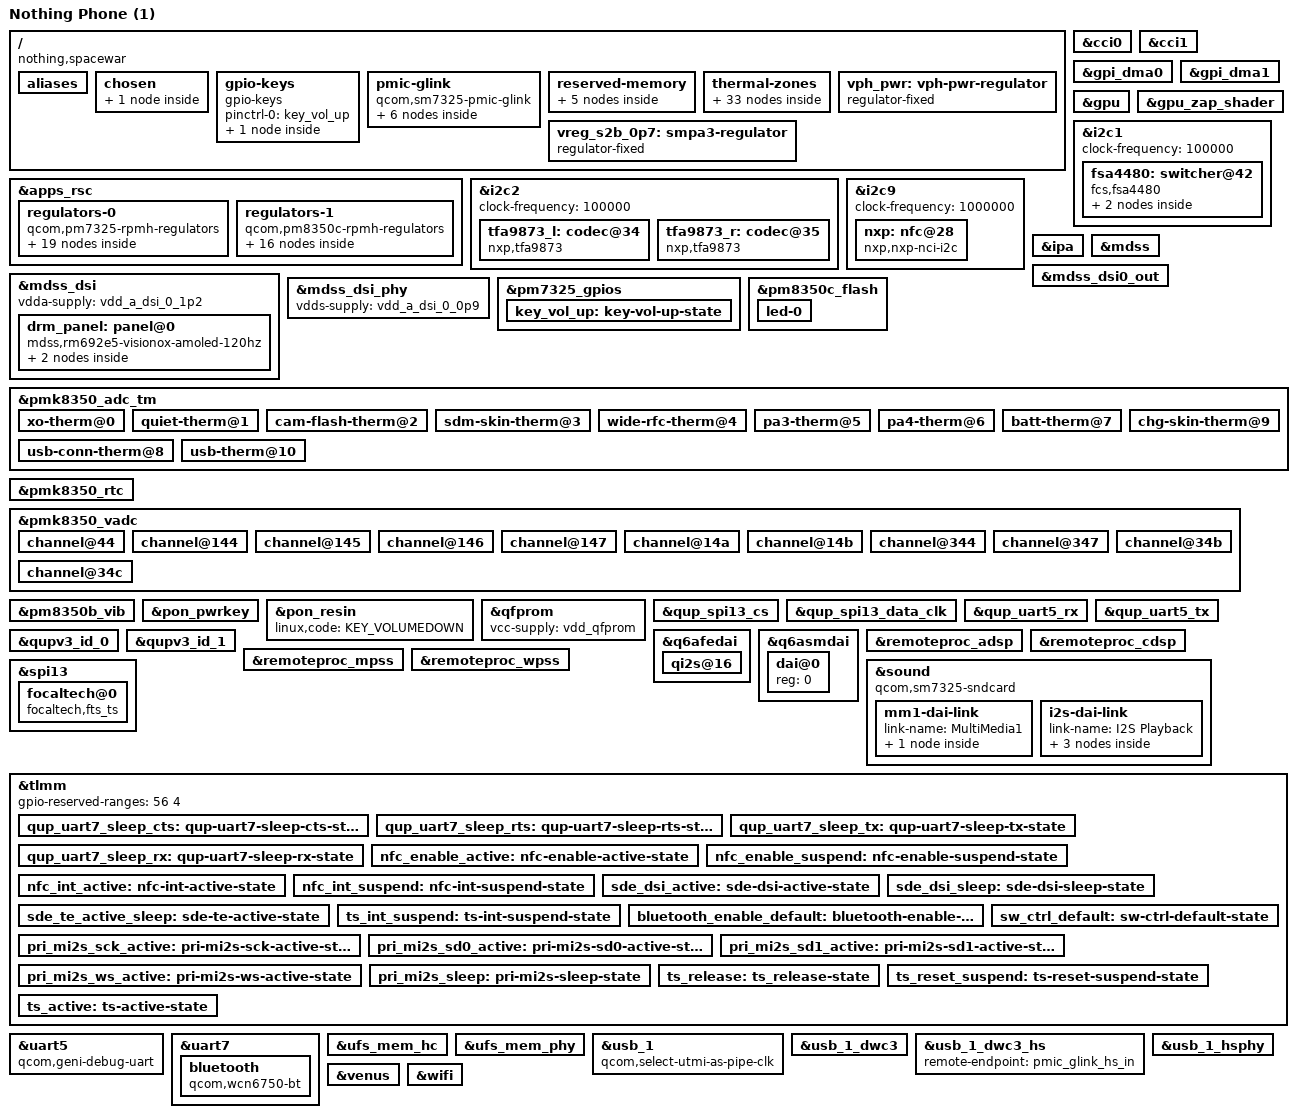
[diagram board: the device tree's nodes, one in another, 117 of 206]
// SPDX-License-Identifier: BSD-3-Clause
/*
 * Copyright (c) 2024, Eugene Lepshy <fekz115@gmail.com>
 * Copyright (c) 2024, Danila Tikhonov <danila@jiaxyga.com>
 */

/dts-v1/;

#include <dt-bindings/arm/qcom,ids.h>
#include <dt-bindings/gpio/gpio.h>
#include <dt-bindings/regulator/qcom,rpmh-regulator.h>
#include <dt-bindings/sound/qcom,q6afe.h>
#include <dt-bindings/sound/qcom,q6asm.h>
#include <dt-bindings/leds/common.h>

#include <dt-bindings/iio/qcom,spmi-adc7-pm7325.h>
#include <dt-bindings/iio/qcom,spmi-adc7-pm8350b.h>
#include <dt-bindings/iio/qcom,spmi-adc7-pmk8350.h>
#include <dt-bindings/pinctrl/qcom,pmic-gpio.h>
#include "sm7325.dtsi"
#include "pm7325.dtsi"
#include "pm8350b.dtsi" /* PM7325B */
#include "pm8350c.dtsi" /* PM7350C */
#include "pmk8350.dtsi" /* PMK7325 */

/delete-node/ &rmtfs_mem;

/ {
	model = "Nothing Phone (1)";
	compatible = "nothing,spacewar", "qcom,sm7325";
	qcom,msm-id = <QCOM_ID_SM7325 0x10000>;
	qcom,board-id = <0x1000b 0>;
	chassis-type = "handset";

	aliases {
		serial0 = &uart5;
		serial1 = &uart7;
	};

	chosen {
		#address-cells = <2>;
		#size-cells = <2>;
		ranges;

		stdout-path = "serial0:115200n8";
		bootargs = "earlycon console=tty0 PMOS_NOSPLASH";

		framebuffer@e1000000 {
			compatible = "simple-framebuffer";
			reg = <0x0 0xe1000000 0x0 (1080 * 2400 * 4)>;
			width = <1080>;
			height = <2400>;
			stride = <(1080 * 4)>;
			format = "a8r8g8b8";
		};
	};

	gpio-keys {
		compatible = "gpio-keys";

		pinctrl-0 = <&key_vol_up>;
		pinctrl-names = "default";

		key-volume-up {
			label = "Volume up";
			gpios = <&pm7325_gpios 6 GPIO_ACTIVE_LOW>;
			linux,code = <KEY_VOLUMEUP>;
		};
	};

	pmic-glink {
		compatible = "qcom,sm7325-pmic-glink",
			     "qcom,pmic-glink";

		#address-cells = <1>;
		#size-cells = <0>;

		connector@0 {
			compatible = "usb-c-connector";
			reg = <0>;
			power-role = "dual";
			data-role = "dual";

			ports {
				#address-cells = <1>;
				#size-cells = <0>;

				port@0 {
					reg = <0>;

					pmic_glink_hs_in: endpoint {
						remote-endpoint = <&usb_1_dwc3_hs>;
					};
				};

				port@1 {
					reg = <1>;

					pmic_glink_sbu: endpoint {
						remote-endpoint = <&fsa4480_sbu_mux>;
					};
				};
			};
		};
	};

	reserved-memory {
		#address-cells = <2>;
		#size-cells = <2>;
		ranges;

		ramoops@83a00000 {
			compatible = "ramoops";
			reg = <0x0 0x83a00000 0x0 0x400000>;
			pmsg-size = <0x200000>;
			mem-type = <0x02>;
			console-size = <0x200000>;
		};

		cdsp_mem: cdsp@88f00000 {
			reg = <0x0 0x88f00000 0x0 0x1e00000>;
			no-map;
		};

		removed_mem: removed@c0000000 {
			reg = <0x0 0xc0000000 0x0 0x5100000>;
			no-map;
		};

		framebuffer@e1000000 {
			reg = <0x0 0xe1000000 0x0 (1080 * 2400 * 4)>;
			no-map;
		};

		rmtfs_mem: rmtfs@f8500000 {
			compatible = "qcom,rmtfs-mem";
			reg = <0x0 0xf8500000 0x0 0x600000>;
			no-map;

			qcom,client-id = <1>;
			qcom,vmid = <QCOM_SCM_VMID_MSS_MSA>,
				    <QCOM_SCM_VMID_NAV>;
		};
	};

	thermal-zones {
		batt-thermal {
			polling-delay-passive = <0>;
			polling-delay = <0>;
			thermal-sensors = <&pmk8350_adc_tm 7>;

			trips {
				active-config0 {
					temperature = <125000>;
					hysteresis = <1000>;
					type = "passive";
				};
			};
		};

		camera-thermal {
			polling-delay-passive = <0>;
			polling-delay = <0>;
			thermal-sensors = <&pmk8350_adc_tm 2>;

			trips {
				active-config0 {
					temperature = <125000>;
					hysteresis = <1000>;
					type = "passive";
				};
			};
		};

		chg-skin-thermal {
			polling-delay-passive = <0>;
			polling-delay = <0>;
			thermal-sensors = <&pmk8350_adc_tm 9>;

			trips {
				active-config0 {
					temperature = <125000>;
					hysteresis = <1000>;
					type = "passive";
				};
			};
		};

		conn-thermal {
			polling-delay-passive = <0>;
			polling-delay = <0>;
			thermal-sensors = <&pmk8350_adc_tm 8>;

			trips {
				active-config0 {
					temperature = <125000>;
					hysteresis = <1000>;
					type = "passive";
				};
			};
		};

		pa3-thermal {
			polling-delay-passive = <0>;
			polling-delay = <0>;
			thermal-sensors = <&pmk8350_adc_tm 5>;

			trips {
				active-config0 {
					temperature = <125000>;
					hysteresis = <1000>;
					type = "passive";
				};
			};
		};

		pa4-thermal {
			polling-delay-passive = <0>;
			polling-delay = <0>;
			thermal-sensors = <&pmk8350_adc_tm 6>;

			trips {
				active-config0 {
					temperature = <125000>;
					hysteresis = <1000>;
					type = "passive";
				};
			};
		};

		quiet-thermal {
			polling-delay-passive = <0>;
			polling-delay = <0>;
			thermal-sensors = <&pmk8350_adc_tm 1>;

			trips {
				active-config0 {
					temperature = <125000>;
					hysteresis = <1000>;
					type = "passive";
				};
			};
		};

		rear-cam-thermal {
			polling-delay-passive = <0>;
			polling-delay = <0>;
			thermal-sensors = <&pmk8350_adc_tm 4>;

			trips {
				active-config0 {
					temperature = <125000>;
					hysteresis = <1000>;
					type = "passive";
				};
			};
		};

		sdm-skin-thermal {
			polling-delay-passive = <0>;
			polling-delay = <0>;
			thermal-sensors = <&pmk8350_adc_tm 3>;

			trips {
				active-config0 {
					temperature = <125000>;
					hysteresis = <1000>;
					type = "passive";
				};
			};
		};

		usb-thermal {
			polling-delay-passive = <0>;
			polling-delay = <0>;
			thermal-sensors = <&pmk8350_adc_tm 10>;

			trips {
				active-config0 {
					temperature = <125000>;
					hysteresis = <1000>;
					type = "passive";
				};
			};
		};

		xo-thermal {
			polling-delay-passive = <0>;
			polling-delay = <0>;
			thermal-sensors = <&pmk8350_adc_tm 0>;

			trips {
				active-config0 {
					temperature = <125000>;
					hysteresis = <1000>;
					type = "passive";
				};
			};
		};
	};

	vph_pwr: vph-pwr-regulator {
		compatible = "regulator-fixed";
		regulator-name = "vph_pwr";
		regulator-min-microvolt = <3700000>;
		regulator-max-microvolt = <3700000>;
	};

	// S2B is really ebi.lvl but it's there for supply map completeness sake.
	vreg_s2b_0p7: smpa3-regulator {
		compatible = "regulator-fixed";
		regulator-name = "vreg_s2b_0p7";

		regulator-min-microvolt = <65535>;
		regulator-max-microvolt = <65535>;
		regulator-always-on;
		vin-supply = <&vph_pwr>;
	};
};

&apps_rsc {
	regulators-0 {
		compatible = "qcom,pm7325-rpmh-regulators";
		qcom,pmic-id = "b";

		vdd-s1-supply = <&vph_pwr>;
		vdd-s2-supply = <&vph_pwr>;
		vdd-s7-supply = <&vph_pwr>;
		vdd-s8-supply = <&vph_pwr>;

		vdd-l1-l4-l12-l15-supply = <&vreg_s7b_0p952>;
		vdd-l2-l7-supply = <&vreg_bob>;
		vdd-l3-supply = <&vreg_s2b_0p7>;
		vdd-l5-supply = <&vreg_s2b_0p7>;
		vdd-l6-l9-l10-supply = <&vreg_s8b_1p256>;
		vdd-l8-supply = <&vreg_s7b_0p952>;
		vdd-l11-l17-l18-l19-supply = <&vreg_s1b_1p856>;
		vdd-l13-supply = <&vreg_s7b_0p952>;
		vdd-l14-l16-supply = <&vreg_s8b_1p256>;

		/*
		 * S2, L4-L5 are ARCs:
		 * S2 - ebi.lvl,
		 * L4 - lmx.lvl,
		 * l5 - lcx.lvl.
		 *
		 * L10 are unused.
		 */

		vdd19_pmu_rfa_i:
		vreg_s1b_1p856: smps1 {
			regulator-min-microvolt = <1840000>;
			regulator-max-microvolt = <2040000>;
		};

		vreg_s7b_0p952: smps7 {
			regulator-min-microvolt = <535000>;
			regulator-max-microvolt = <1120000>;
		};

		vdd13_pmu_rfa_i:
		vreg_s8b_1p256: smps8 {
			regulator-min-microvolt = <1200000>;
			regulator-max-microvolt = <1500000>;
			regulator-initial-mode = <RPMH_REGULATOR_MODE_RET>;
		};

		vreg_l1b_0p912: ldo1 {
			regulator-min-microvolt = <825000>;
			regulator-max-microvolt = <925000>;
			regulator-initial-mode = <RPMH_REGULATOR_MODE_HPM>;
		};

		vdd_a_usbhs_3p1:
		vreg_l2b_3p072: ldo2 {
			regulator-min-microvolt = <2700000>;
			regulator-max-microvolt = <3544000>;
			regulator-initial-mode = <RPMH_REGULATOR_MODE_HPM>;
		};

		vreg_l3b_0p6: ldo3 {
			regulator-min-microvolt = <312000>;
			regulator-max-microvolt = <910000>;
			regulator-initial-mode = <RPMH_REGULATOR_MODE_HPM>;
		};

		vdd_a_dsi_0_1p2:
		vdd_a_ufs_0_1p2:
		vreg_l6b_1p2: ldo6 {
			regulator-min-microvolt = <1140000>;
			regulator-max-microvolt = <1260000>;
			regulator-initial-mode = <RPMH_REGULATOR_MODE_HPM>;
			regulator-allow-set-load;
			regulator-allowed-modes = <RPMH_REGULATOR_MODE_LPM
						   RPMH_REGULATOR_MODE_HPM>;
		};

		vreg_l7b_2p96: ldo7 {
			regulator-min-microvolt = <2952000>;
			regulator-max-microvolt = <2952000>;
			regulator-initial-mode = <RPMH_REGULATOR_MODE_HPM>;
			regulator-allow-set-load;
			regulator-allowed-modes = <RPMH_REGULATOR_MODE_LPM
						   RPMH_REGULATOR_MODE_HPM>;
		};

		vreg_l8b_0p904: ldo8 {
			regulator-min-microvolt = <870000>;
			regulator-max-microvolt = <970000>;
			regulator-initial-mode = <RPMH_REGULATOR_MODE_HPM>;
		};

		vreg_l9b_1p2: ldo9 {
			regulator-min-microvolt = <1200000>;
			regulator-max-microvolt = <1304000>;
			regulator-initial-mode = <RPMH_REGULATOR_MODE_HPM>;
			regulator-allow-set-load;
			regulator-allowed-modes = <RPMH_REGULATOR_MODE_LPM
						   RPMH_REGULATOR_MODE_HPM>;
		};

		vreg_l11b_1p776: ldo11 {
			regulator-min-microvolt = <1504000>;
			regulator-max-microvolt = <2000000>;
			regulator-initial-mode = <RPMH_REGULATOR_MODE_HPM>;
		};

		vreg_l12b_0p8: ldo12 {
			regulator-min-microvolt = <751000>;
			regulator-max-microvolt = <824000>;
			regulator-initial-mode = <RPMH_REGULATOR_MODE_HPM>;
		};

		vreg_l13b_0p8: ldo13 {
			regulator-min-microvolt = <530000>;
			regulator-max-microvolt = <824000>;
			regulator-initial-mode = <RPMH_REGULATOR_MODE_HPM>;
		};

		vreg_l14b_1p2: ldo14 {
			regulator-min-microvolt = <1080000>;
			regulator-max-microvolt = <1304000>;
			regulator-initial-mode = <RPMH_REGULATOR_MODE_HPM>;
		};

		vreg_l15b_0p88: ldo15 {
			regulator-min-microvolt = <765000>;
			regulator-max-microvolt = <1020000>;
			regulator-initial-mode = <RPMH_REGULATOR_MODE_HPM>;
		};

		vreg_l16b_1p2: ldo16 {
			regulator-min-microvolt = <1100000>;
			regulator-max-microvolt = <1300000>;
			regulator-initial-mode = <RPMH_REGULATOR_MODE_HPM>;
		};

		vreg_l17b_1p8: ldo17 {
			regulator-min-microvolt = <1700000>;
			regulator-max-microvolt = <1900000>;
			regulator-initial-mode = <RPMH_REGULATOR_MODE_HPM>;
		};

		vreg_l18b_1p8: ldo18 {
			regulator-min-microvolt = <1800000>;
			regulator-max-microvolt = <2000000>;
			regulator-initial-mode = <RPMH_REGULATOR_MODE_HPM>;
		};

		vreg_l19b_1p8: ldo19 {
			regulator-min-microvolt = <1800000>;
			regulator-max-microvolt = <2000000>;
			regulator-initial-mode = <RPMH_REGULATOR_MODE_HPM>;
		};
	};

	regulators-1 {
		compatible = "qcom,pm8350c-rpmh-regulators";
		qcom,pmic-id = "c";

		vdd-s1-supply = <&vph_pwr>;
		vdd-s2-supply = <&vph_pwr>;
		vdd-s5-supply = <&vph_pwr>;
		vdd-s7-supply = <&vph_pwr>;
		vdd-s9-supply = <&vph_pwr>;
		vdd-s10-supply = <&vph_pwr>;

		vdd-l1-l12-supply = <&vreg_s1b_1p856>;
		vdd-l2-l8-supply = <&vreg_s1b_1p856>;
		/*
		 * Doesn't work :/
		 * vdd-l3-l4-l5-l7-l13-supply = <&vreg_bob>;
		 */
		vdd-l6-l9-l11-supply = <&vreg_bob>;
		vdd-l10-supply = <&vreg_s7b_0p952>;

		vdd-bob-supply = <&vph_pwr>;

		/*
		 * S2, S5, S7, S10 are ARCs:
		 * S2 - cx.lvl,
		 * S5 - mss.lvl,
		 * S7 - gfx.lvl,
		 * S10 - mx.lvl.
		 */

		vreg_s1c_2p2: smps1 {
			regulator-min-microvolt = <2190000>;
			regulator-max-microvolt = <2210000>;
		};

		vreg_s9c_0p676: smps9 {
			regulator-min-microvolt = <1010000>;
			regulator-max-microvolt = <1170000>;
		};

		vdd_a_usbhs_1p8:
		vdd_qfprom:
		vreg_l1c_1p8: ldo1 {
			regulator-min-microvolt = <1800000>;
			regulator-max-microvolt = <1980000>;
			regulator-initial-mode = <RPMH_REGULATOR_MODE_HPM>;
		};

		vreg_l2c_1p8: ldo2 {
			regulator-min-microvolt = <1620000>;
			regulator-max-microvolt = <1980000>;
			regulator-initial-mode = <RPMH_REGULATOR_MODE_HPM>;
		};

		vreg_l3c_3p0: ldo3 {
			regulator-min-microvolt = <2800000>;
			regulator-max-microvolt = <3540000>;
			regulator-initial-mode = <RPMH_REGULATOR_MODE_HPM>;
			regulator-always-on;
		};

		vreg_l4c_1p8_3p0: ldo4 {
			regulator-min-microvolt = <1620000>;
			regulator-max-microvolt = <3300000>;
			regulator-initial-mode = <RPMH_REGULATOR_MODE_HPM>;
		};

		vreg_l5c_1p8_3p0: ldo5 {
			regulator-min-microvolt = <1620000>;
			regulator-max-microvolt = <3300000>;
			regulator-initial-mode = <RPMH_REGULATOR_MODE_HPM>;
		};

		vreg_l6c_2p96: ldo6 {
			regulator-min-microvolt = <1650000>;
			regulator-max-microvolt = <3544000>;
			regulator-initial-mode = <RPMH_REGULATOR_MODE_HPM>;
		};

		vreg_l7c_3p0: ldo7 {
			regulator-min-microvolt = <3000000>;
			regulator-max-microvolt = <3544000>;
			regulator-initial-mode = <RPMH_REGULATOR_MODE_HPM>;
		};

		vreg_l8c_1p8: ldo8 {
			regulator-min-microvolt = <1620000>;
			regulator-max-microvolt = <2000000>;
			regulator-initial-mode = <RPMH_REGULATOR_MODE_HPM>;
			regulator-always-on;
		};

		vreg_l9c_2p96: ldo9 {
			regulator-min-microvolt = <2700000>;
			regulator-max-microvolt = <3544000>;
			regulator-initial-mode = <RPMH_REGULATOR_MODE_HPM>;
		};

		vdd_a_dsi_0_0p9:
		vdd_a_dsi_0_pll_0p9:
		vdd_a_ufs_0_core:
		vdd_a_usbhs_core:
		vreg_l10c_0p88: ldo10 {
			regulator-min-microvolt = <720000>;
			regulator-max-microvolt = <1050000>;
			regulator-initial-mode = <RPMH_REGULATOR_MODE_HPM>;
			regulator-allow-set-load;
			regulator-allowed-modes = <RPMH_REGULATOR_MODE_LPM
						   RPMH_REGULATOR_MODE_HPM>;
		};

		vreg_l11c_2p8: ldo11 {
			regulator-min-microvolt = <2800000>;
			regulator-max-microvolt = <3544000>;
			regulator-initial-mode = <RPMH_REGULATOR_MODE_HPM>;
		};

		vreg_l12c_1p8: ldo12 {
			regulator-min-microvolt = <1650000>;
			regulator-max-microvolt = <2000000>;
			regulator-initial-mode = <RPMH_REGULATOR_MODE_HPM>;
		};

		vreg_l13c_3p0: ldo13 {
			regulator-min-microvolt = <2700000>;
			regulator-max-microvolt = <3544000>;
			regulator-initial-mode = <RPMH_REGULATOR_MODE_HPM>;
		};

		vdd_flash:
		vdd_iris_rgb:
		vdd_mic_bias:
		vreg_bob: bob {
			regulator-min-microvolt = <3008000>;
			regulator-max-microvolt = <3960000>;
			regulator-initial-mode = <RPMH_REGULATOR_MODE_AUTO>;
		};
	};
};

&cci0 {
	status = "okay";
};

&cci1 {
	status = "okay";
};

&gpi_dma0 {
	status = "okay";
};

&gpi_dma1 {
	status = "okay";
};

&gpu {
	status = "okay";
};

&gpu_zap_shader {
	firmware-name = "qcom/sm7325/nothing/spacewar/a660_zap.mbn";
};

&i2c1 {
	clock-frequency = <100000>;
	status = "okay";

	/* awinic,aw210xx_led @ 20 */

	fsa4480: switcher@42 {
		compatible = "fcs,fsa4480";
		reg = <0x42>;

		vcc-supply = <&vreg_bob>;

		mode-switch;
		orientation-switch;

		port {
			fsa4480_sbu_mux: endpoint {
				remote-endpoint = <&pmic_glink_sbu>;
			};
		};
	};
};

&i2c2 {
	clock-frequency = <100000>;
	status = "okay";

	tfa9873_l: codec@34 { /* EAR */
		compatible = "nxp,tfa9873", "nxp,tfa9872";
		reg = <0x34>;
		reset-gpio = <&tlmm 101 GPIO_ACTIVE_HIGH>;

		#sound-dai-cells = <1>;
	};

	tfa9873_r: codec@35 { /* SPK */
		compatible = "nxp,tfa9873", "nxp,tfa9872";
		reg = <0x35>;
		reset-gpio = <&tlmm 101 GPIO_ACTIVE_HIGH>;

		#sound-dai-cells = <1>;
	};
};

&i2c9 {
	clock-frequency = <1000000>;
	status = "okay";

	nxp: nfc@28 {
		compatible = "nxp,nxp-nci-i2c";
		reg = <0x28>;

		interrupt-parent = <&tlmm>;
		interrupts = <41 IRQ_TYPE_NONE>;

		enable-gpios = <&tlmm 38 GPIO_ACTIVE_HIGH>;
		firmware-gpios = <&tlmm 40 GPIO_ACTIVE_HIGH>;

		pinctrl-names = "default", "sleep";
		pinctrl-0 = <&nfc_enable_active>, <&nfc_int_active>;
		pinctrl-1 = <&nfc_enable_suspend>, <&nfc_int_suspend>;
	};
};

&ipa {
	qcom,gsi-loader = "self";
	memory-region = <&ipa_fw_mem>;
	firmware-name = "qcom/sm7325/nothing/spacewar/ipa_fws.mbn";
	status = "okay";
};

&mdss {
	status = "okay";
};

&mdss_dsi {
	vdda-supply = <&vdd_a_dsi_0_1p2>;
	status = "okay";

	drm_panel: panel@0 {
		compatible = "mdss,rm692e5-visionox-amoled-120hz";
		reg = <0>;

		reset-gpios = <&tlmm 44 GPIO_ACTIVE_LOW>;

		vdd-supply = <&vreg_l13c_3p0>;
		vddio-supply = <&vreg_l12c_1p8>;

		pinctrl-0 = <&sde_dsi_active &sde_te_active_sleep>;
		pinctrl-1 = <&sde_dsi_sleep &sde_te_active_sleep>;
		pinctrl-names = "default", "sleep";

		port {
			panel_in: endpoint {
				remote-endpoint = <&mdss_dsi0_out>;
			};
		};
	};
};

&mdss_dsi0_out {
	data-lanes = <0 1 2 3>;
	remote-endpoint = <&panel_in>;
};

&mdss_dsi_phy {
	vdds-supply = <&vdd_a_dsi_0_0p9>;
	status = "okay";
};

&pm7325_gpios {
	gpio-line-names = "NC", /* GPIO_1 */
			  "PA_THERM3",
			  "PA_THERM4",
			  "NC",
			  "NC",
			  "KEY_VOL_UP",
			  "NC",
			  "NC",
			  "NC",
			  "NC"; /* GPIO_10 */

	key_vol_up: key-vol-up-state {
		pins = "gpio6";
		function = PMIC_GPIO_FUNC_NORMAL;
		bias-pull-up;
		input-enable;
		power-source = <1>;
	};
};

&pm8350c_flash {
	status = "okay";

	led-0 {
		function = LED_FUNCTION_FLASH;
		color = <LED_COLOR_ID_WHITE>;
		led-sources = <1>, <4>;
		led-max-microamp = <500000>;
		flash-max-microamp = <1500000>;
		flash-max-timeout-us = <1280000>;
	};
};

&pmk8350_adc_tm {
	status = "okay";

	/* PMK8350 */
	xo-therm@0 {
		reg = <0>;
		io-channels = <&pmk8350_vadc PMK8350_ADC7_AMUX_THM1_100K_PU>;
		qcom,ratiometric;
		qcom,hw-settle-time-us = <200>;
	};

	/* PM7325 */
	quiet-therm@1 {
		reg = <1>;
		io-channels = <&pmk8350_vadc PM7325_ADC7_AMUX_THM1_100K_PU>;
		qcom,ratiometric;
		qcom,hw-settle-time-us = <200>;
	};

	cam-flash-therm@2 {
		reg = <2>;
		io-channels = <&pmk8350_vadc PM7325_ADC7_AMUX_THM2_100K_PU>;
		qcom,ratiometric;
		qcom,hw-settle-time-us = <200>;
	};

	sdm-skin-therm@3 {
		reg = <3>;
		io-channels = <&pmk8350_vadc PM7325_ADC7_AMUX_THM3_100K_PU>;
		qcom,ratiometric;
		qcom,hw-settle-time-us = <200>;
	};

	wide-rfc-therm@4 {
		reg = <4>;
		io-channels = <&pmk8350_vadc PM7325_ADC7_AMUX_THM4_100K_PU>;
		qcom,ratiometric;
		qcom,hw-settle-time-us = <200>;
	};

	pa3-therm@5 {
		reg = <5>;
		io-channels = <&pmk8350_vadc PM7325_ADC7_GPIO1_100K_PU>;
		qcom,ratiometric;
		qcom,hw-settle-time-us = <200>;
	};

	pa4-therm@6 {
		reg = <6>;
		io-channels = <&pmk8350_vadc PM7325_ADC7_GPIO2_100K_PU>;
		qcom,ratiometric;
		qcom,hw-settle-time-us = <200>;
	};

	/* PM8350B */
	batt-therm@7 {
		reg = <7>;
		io-channels = <&pmk8350_vadc PM8350B_ADC7_AMUX_THM1_100K_PU>;
		qcom,ratiometric;
		qcom,hw-settle-time = <200>;
	};

	usb-conn-therm@8 {
		reg = <8>;
		io-channels = <&pmk8350_vadc PM8350B_ADC7_AMUX_THM4_100K_PU>;
		qcom,ratiometric;
		qcom,hw-settle-time-us = <200>;
	};

	chg-skin-therm@9 {
		reg = <9>;
		io-channels = <&pmk8350_vadc PM8350B_ADC7_GPIO2_100K_PU>;
		qcom,ratiometric;
		qcom,hw-settle-time-us = <200>;
	};

	usb-therm@10 {
		reg = <10>;
		io-channels = <&pmk8350_vadc PM8350B_ADC7_GPIO3_100K_PU>;
		qcom,ratiometric;
		qcom,hw-settle-time = <200>;
	};
};

&pmk8350_rtc {
	status = "okay";
};

&pmk8350_vadc {
	/* PMK8350 */
	channel@44 {
		reg = <PMK8350_ADC7_AMUX_THM1_100K_PU>;
		qcom,ratiometric;
		qcom,hw-settle-time = <200>;
		qcom,pre-scaling = <1 1>;
		label = "pmk8350_xo_therm";
	};

	/* PM7325 */
	channel@144 {
		reg = <PM7325_ADC7_AMUX_THM1_100K_PU>;
		qcom,ratiometric;
		qcom,hw-settle-time = <200>;
		qcom,pre-scaling = <1 1>;
		label = "pm7325_quiet_therm";
	};

	channel@145 {
		reg = <PM7325_ADC7_AMUX_THM2_100K_PU>;
		qcom,ratiometric;
		qcom,hw-settle-time = <200>;
		qcom,pre-scaling = <1 1>;
		label = "pm7325_cam_flash_therm";
	};

	channel@146 {
		reg = <PM7325_ADC7_AMUX_THM3_100K_PU>;
		qcom,ratiometric;
		qcom,hw-settle-time = <200>;
		qcom,pre-scaling = <1 1>;
		label = "pm7325_sdm_skin_therm";
	};

	channel@147 {
		reg = <PM7325_ADC7_AMUX_THM4_100K_PU>;
		qcom,ratiometric;
		qcom,hw-settle-time = <200>;
		qcom,pre-scaling = <1 1>;
		label = "pm7325_wide_rfc_therm";
	};

	channel@14a {
		reg = <PM7325_ADC7_GPIO1_100K_PU>;
		qcom,ratiometric;
		qcom,hw-settle-time = <200>;
		qcom,pre-scaling = <1 1>;
		label = "pm7325_pa3_therm";
	};

	channel@14b {
		reg = <PM7325_ADC7_GPIO2_100K_PU>;
		qcom,ratiometric;
		qcom,hw-settle-time = <200>;
		qcom,pre-scaling = <1 1>;
		label = "pm7325_pa4_therm";
	};

	/* PM8350B */
	channel@344 {
		reg = <PM8350B_ADC7_AMUX_THM1_100K_PU>;
		qcom,ratiometric;
		qcom,hw-settle-time = <200>;
		qcom,pre-scaling = <1 1>;
		label = "pm8350b_batt_therm";
	};

	channel@347 {
		reg = <PM8350B_ADC7_AMUX_THM4_100K_PU>;
		qcom,ratiometric;
		qcom,hw-settle-time = <200>;
		qcom,pre-scaling = <1 1>;
		label = "pm8350b_usb_conn_therm";
	};

	channel@34b {
		reg = <PM8350B_ADC7_GPIO2_100K_PU>;
		qcom,ratiometric;
		qcom,hw-settle-time = <200>;
		qcom,pre-scaling = <1 1>;
		label = "pm8350b_chg_skin_therm";
	};

	channel@34c {
		reg = <PM8350B_ADC7_GPIO3_100K_PU>;
		qcom,ratiometric;
		qcom,hw-settle-time = <200>;
		qcom,pre-scaling = <1 1>;
		label = "pm8350b_usb_therm2";
	};
};

&pm8350b_vib {
	status = "okay";
};

&pon_pwrkey {
	status = "okay";
};

&pon_resin {
	linux,code = <KEY_VOLUMEDOWN>;
	status = "okay";
};

&qfprom {
	vcc-supply = <&vdd_qfprom>;
};

&qup_spi13_cs {
	drive-strength = <6>;
	bias-disable;
};

&qup_spi13_data_clk {
	drive-strength = <6>;
	bias-disable;
};

&qup_uart5_rx {
	drive-strength = <2>;
	bias-disable;
};

&qup_uart5_tx {
	drive-strength = <2>;
	bias-disable;
};

&qupv3_id_0 {
	status = "okay";
};

&qupv3_id_1 {
	status = "okay";
};

&q6afedai {
	qi2s@16 {
		reg = <PRIMARY_MI2S_RX>;
		qcom,sd-lines = <1>;
	};
};

&q6asmdai {
	dai@0 {
		reg = <0>;
	};
};

&remoteproc_adsp {
	firmware-name = "qcom/sm7325/nothing/spacewar/adsp.mbn";
	status = "okay";
};

&remoteproc_cdsp {
	firmware-name = "qcom/sm7325/nothing/spacewar/cdsp.mbn";
	status = "okay";
};

&remoteproc_mpss {
	firmware-name = "qcom/sm7325/nothing/spacewar/modem.mbn";
	status = "okay";
};

&remoteproc_wpss {
	firmware-name = "qcom/sm7325/nothing/spacewar/wpss.mbn";
	status = "okay";
};

&spi13 {
	status = "okay";

	focaltech@0 {
		status = "okay";
		compatible = "focaltech,fts_ts";
		reg = <0x0>;
		spi-max-frequency = <6000000>;
		interrupt-parent = <&tlmm>;
		interrupts = <81 IRQ_TYPE_EDGE_FALLING>;
		focaltech,reset-gpio = <&tlmm 105 GPIO_ACTIVE_HIGH>;
		focaltech,irq-gpio = <&tlmm 81 IRQ_TYPE_EDGE_FALLING>;
		focaltech,display-coords = <0 0 1080 2400>;
		focaltech,max-touch-number = <10>;
		focaltech,ic-type = <0x3658d488>;

		vdd-supply = <&vreg_l3c_3p0>;
		iovdd-supply = <&vreg_l8c_1p8>;

		pinctrl-0 = <&ts_active>;
		pinctrl-1 = <&ts_int_suspend &ts_reset_suspend>;
		pinctrl-2 = <&ts_release>;
		pinctrl-names = "pmx_ts_active",
				"pmx_ts_suspend",
				"pmx_ts_release";
		focaltech,trusted-touch-mode = "vm_mode";
		focaltech,touch-environment = "pvm";
		focaltech,trusted-touch-spi-irq = <601>;
		focaltech,trusted-touch-io-bases = <0xf134000 0xf135000
						    0xf136000 0xf137000
						    0xf169000 0xf151000
						    0xa94000 0x00a10000>;
		focaltech,trusted-touch-io-sizes = <0x1000 0x1000 0x1000 0x1000
						    0x1000 0x1000 0x1000 0x4000>;
		//panel = <&drm_panel>;
	};
};

&sound {
	compatible = "qcom,sm7325-sndcard",
		     "qcom,sm8250-sndcard";
	pinctrl-0 = <&pri_mi2s_sck_active &pri_mi2s_ws_active
		     &pri_mi2s_sd0_active &pri_mi2s_sd1_active>;
	pinctrl-1 = <&pri_mi2s_sleep>;
	pinctrl-names = "default", "sleep";
	model = "NP1";

	mm1-dai-link {
		link-name = "MultiMedia1";
		cpu {
			sound-dai = <&q6asmdai MSM_FRONTEND_DAI_MULTIMEDIA1>;
		};
	};

	i2s-dai-link {
		link-name = "I2S Playback";
		cpu {
			sound-dai = <&q6afedai PRIMARY_MI2S_RX>;
		};

		platform {
			sound-dai = <&q6routing>;
		};

		codec {
			sound-dai = <&tfa9873_r 0>, <&tfa9873_l 0>;
		};
	};
};

&tlmm {
	/* 56-59: fingerprint reader (SPI) */
	gpio-reserved-ranges = <56 4>;

	qup_uart7_sleep_cts: qup-uart7-sleep-cts-state {
		pins = "gpio28";
		function = "gpio";
		/*
		 * Configure a bias-bus-hold on CTS to lower power
		 * usage when Bluetooth is turned off. Bus hold will
		 * maintain a low power state regardless of whether
		 * the Bluetooth module drives the pin in either
		 * direction or leaves the pin fully unpowered.
		 */
		bias-bus-hold;
	};

	qup_uart7_sleep_rts: qup-uart7-sleep-rts-state {
		pins = "gpio29";
		function = "gpio";
		/*
		 * Configure pull-down on RTS. As RTS is active low
		 * signal, pull it low to indicate the BT SoC that it
		 * can wakeup the system anytime from suspend state by
		 * pulling RX low (by sending wakeup bytes).
		 */
		bias-pull-down;
	};

	qup_uart7_sleep_tx: qup-uart7-sleep-tx-state {
		pins = "gpio30";
		function = "gpio";
		/*
		 * Configure pull-up on TX when it isn't actively driven
		 * to prevent BT SoC from receiving garbage during sleep.
		 */
		bias-pull-up;
	};

	qup_uart7_sleep_rx: qup-uart7-sleep-rx-state {
		pins = "gpio31";
		function = "gpio";
		/*
		 * Configure a pull-up on RX. This is needed to avoid
		 * garbage data when the TX pin of the Bluetooth module
		 * is floating which may cause spurious wakeups.
		 */
		bias-pull-up;
	};

	nfc_enable_active: nfc-enable-active-state {
		pins = "gpio38", "gpio40", "gpio39";
		function = "gpio";
		drive-strength = <2>;
		bias-disable;
	};

	nfc_enable_suspend: nfc-enable-suspend-state {
		pins = "gpio38", "gpio40", "gpio39";
		function = "gpio";
		drive-strength = <2>;
		bias-disable;
	};

	nfc_int_active: nfc-int-active-state {
		pins = "gpio41";
		function = "gpio";
		drive-strength = <2>;
		bias-pull-down;
	};

	nfc_int_suspend: nfc-int-suspend-state {
		pins = "gpio41";
		function = "gpio";
		drive-strength = <2>;
		bias-pull-down;
	};

	sde_dsi_active: sde-dsi-active-state {
		pins = "gpio44";
		function = "gpio";
		drive-strength = <8>;
		bias-disable;
	};

	sde_dsi_sleep: sde-dsi-sleep-state {
		pins = "gpio44";
		function = "gpio";
		drive-strength = <2>;
		bias-pull-down;
	};

	sde_te_active_sleep: sde-te-active-state {
		pins = "gpio80";
		function = "mdp_vsync";
		drive-strength = <2>;
		bias-pull-down;
	};

	ts_int_suspend: ts-int-suspend-state {
		pins = "gpio81";
		function = "gpio";
		drive-strength = <2>;
		bias-pull-down;
	};

	bluetooth_enable_default: bluetooth-enable-default-state {
		pins = "gpio85";
		function = "gpio";
		output-low;
		bias-disable;
	};

	sw_ctrl_default: sw-ctrl-default-state {
		pins = "gpio86";
		function = "gpio";
		bias-pull-down;
	};

	pri_mi2s_sck_active: pri-mi2s-sck-active-state {
		pins = "gpio97";
		function = "mi2s0_sck";
		drive-strength = <8>;
		bias-disable;
		output-high;
	};

	pri_mi2s_sd0_active: pri-mi2s-sd0-active-state {
		pins = "gpio98";
		function = "mi2s0_data0";
		drive-strength = <8>;
		bias-disable;
		output-high;
	};

	pri_mi2s_sd1_active: pri-mi2s-sd1-active-state {
		pins = "gpio99";
		function = "mi2s0_data1";
		drive-strength = <8>;
		bias-disable;
		output-high;
	};

	pri_mi2s_ws_active: pri-mi2s-ws-active-state {
		pins = "gpio100";
		function = "mi2s0_ws";
		drive-strength = <8>;
		bias-disable;
		output-high;
	};

	pri_mi2s_sleep: pri-mi2s-sleep-state {
		pins = "gpio97", "gpio98", "gpio99", "gpio100";
		function = "gpio";
		drive-strength = <2>;
		bias-pull-down;
		input-enable;
	};

	ts_release: ts_release-state {
		pins = "gpio105", "gpio81";
		function = "gpio";
		drive-strength = <2>;
		bias-disable;
	};

	ts_reset_suspend: ts-reset-suspend-state {
		pins = "gpio105";
		function = "gpio";
		drive-strength = <2>;
		bias-pull-down;
	};

	ts_active: ts-active-state {
		pins = "gpio105", "gpio81";
		function = "gpio";
		drive-strength = <8>;
		bias-pull-up;
	};
};

&uart5 {
	compatible = "qcom,geni-debug-uart";
	status = "okay";
};

&uart7 {
	/delete-property/interrupts;
	interrupts-extended = <&intc GIC_SPI 608 IRQ_TYPE_LEVEL_HIGH>,
			      <&tlmm 31 IRQ_TYPE_EDGE_FALLING>;

	pinctrl-1 = <&qup_uart7_sleep_cts>,
		    <&qup_uart7_sleep_rts>,
		    <&qup_uart7_sleep_tx>,
		    <&qup_uart7_sleep_rx>;
	pinctrl-names = "default", "sleep";

	status = "okay";

	bluetooth: bluetooth {
		compatible = "qcom,wcn6750-bt";

		pinctrl-0 = <&bluetooth_enable_default>,
			    <&sw_ctrl_default>;
		pinctrl-names = "default";

		enable-gpios = <&tlmm 85 GPIO_ACTIVE_HIGH>;
		swctrl-gpios = <&tlmm 86 GPIO_ACTIVE_HIGH>;

		vddio-supply = <&vreg_l19b_1p8>;
		vddaon-supply = <&vreg_s7b_0p952>;
		vddbtcxmx-supply = <&vreg_s7b_0p952>;
		vddrfacmn-supply = <&vreg_s7b_0p952>;
		vddrfa0p8-supply = <&vreg_s7b_0p952>;
		vddrfa1p2-supply = <&vdd13_pmu_rfa_i>;
		vddrfa1p7-supply = <&vdd19_pmu_rfa_i>;
		vddrfa2p2-supply = <&vreg_s1c_2p2>;
		vddasd-supply = <&vreg_l11c_2p8>;
		max-speed = <3200000>;

		qcom,local-bd-address-broken;
	};
};

&ufs_mem_hc {
	reset-gpios = <&tlmm 175 GPIO_ACTIVE_LOW>;

	vcc-supply = <&vreg_l7b_2p96>;
	vcc-max-microamp = <800000>;
	/*
	 * Technically l9b enables an eLDO (supplied by s1b) which then powers
	 * VCCQ2 of the UFS.
	 */
	vccq-supply = <&vreg_l9b_1p2>;
	vccq-max-microamp = <900000>;

	status = "okay";
};

&ufs_mem_phy {
	vdda-phy-supply = <&vdd_a_ufs_0_core>;
	vdda-pll-supply = <&vdd_a_ufs_0_1p2>;
	status = "okay";
};

&usb_1 {
	/* USB 2.0 only */
	qcom,select-utmi-as-pipe-clk;
	status = "okay";
};

&usb_1_dwc3 {
	dr_mode = "otg";
	usb-role-switch;
	maximum-speed = "high-speed";
	/* Remove USB3 phy */
	phys = <&usb_1_hsphy>;
	phy-names = "usb2-phy";
};

&usb_1_dwc3_hs {
	remote-endpoint = <&pmic_glink_hs_in>;
};

&usb_1_hsphy {
	vdda-pll-supply = <&vdd_a_usbhs_core>;
	vdda18-supply = <&vdd_a_usbhs_1p8>;
	vdda33-supply = <&vdd_a_usbhs_3p1>;
	status = "okay";
};

&venus {
	firmware-name = "qcom/sm7325/nothing/spacewar/vpu20_1v.mbn";
	status = "okay";
};

&wifi {
	status = "okay";
};
